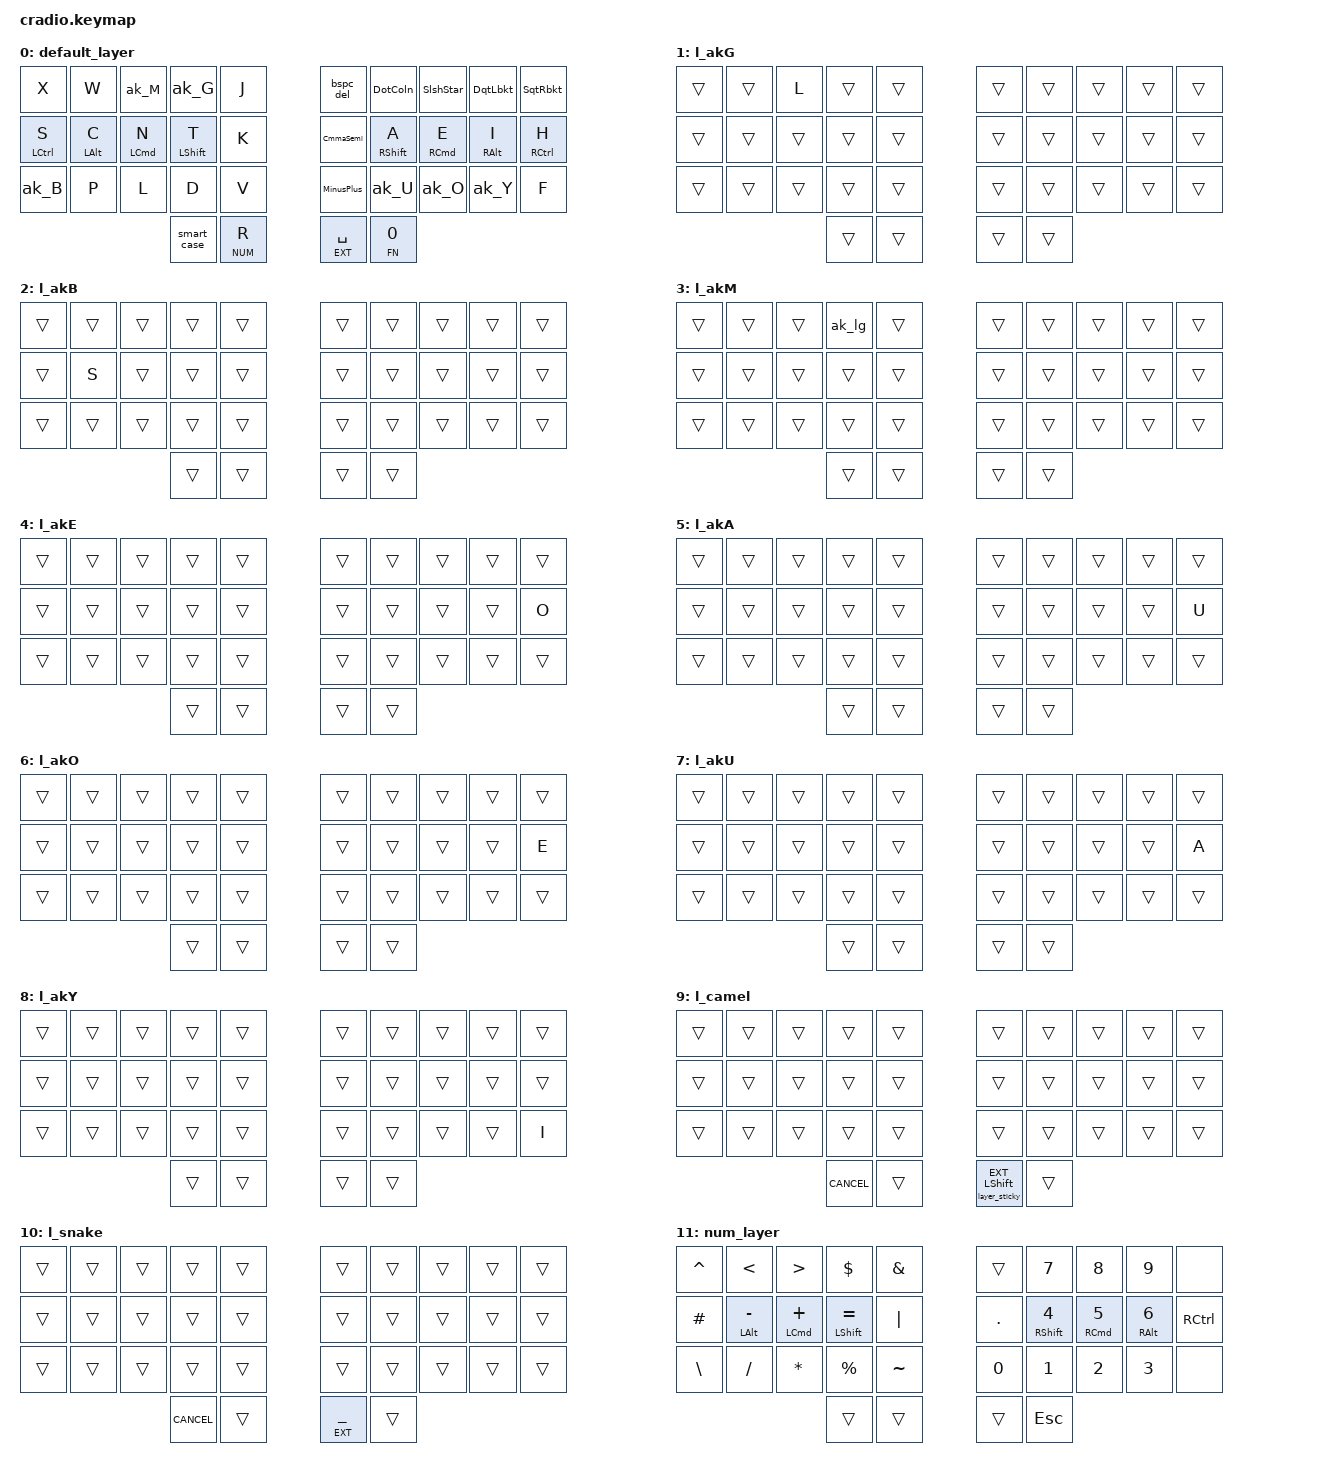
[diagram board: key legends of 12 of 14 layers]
#include <behaviors.dtsi>
#include <dt-bindings/zmk/keys.h>
#include <dt-bindings/zmk/bt.h>

#include "../zmk-nodefree-config/helper.h"
#include "../zmk-nodefree-config/keypos_def/keypos_34keys.h"

#define KEYS_L LT0 LT1 LT2 LT3 LT4 LM0 LM1 LM2 LM3 LM4 LB0 LB1 LB2 LB3 LB4
#define KEYS_R RT0 RT1 RT2 RT3 RT4 RM0 RM1 RM2 RM3 RM4 RB0 RB1 RB2 RB3 RB4
#define KEYS_T LH1 LH0 RH0 RH1

#define XXX &none
#define ___ &trans

/* Global settings */

#define HM_TAPPING_TERM 280
#define HM_TAPPING_TERM_FAST 200
#define LAYER_TAPPING_TERM 200
#define AK_TAPPING_TERM 40
#define LK_TAPPING_TERM 200
#define QUICK_TAP_MS 175

&sk {  // sticky-key config
    release-after-ms = <600>;  // release after 0.6s
    quick-release;             // no double capitalization when rolling keys
};

&sl {  // sticky-layer config
    ignore-modifiers;          // allow chording sticky mods & layers
};

&lt {  // layer-tap config
    flavor = "balanced";
    tapping-term-ms = <LAYER_TAPPING_TERM>;
    quick-tap-ms = <QUICK_TAP_MS>;
};

#define ZMK_MACRO_FAST(NAME, ...) \
    ZMK_BEHAVIOR(NAME, macro, \
        wait-ms = <0>; \
        tap-ms = <0>; \
        bindings = __VA_ARGS__ ; \
    )

ZMK_BEHAVIOR(long_sticky, sticky_key,
    bindings = <&kp>;
    release-after-ms = <5000>;
    quick-release;)

ZMK_BEHAVIOR(layer_sticky, hold_tap,
    flavor = "balanced";
    tapping-term-ms = <LAYER_TAPPING_TERM>;
    quick-tap-ms = <QUICK_TAP_MS>;
    bindings = <&mo>, <&long_sticky>;)

/* Layers */

#define ALPHA 0
#define l_akG 1
#define l_akB 2
#define l_akM 3
#define l_akE 4
#define l_akA 5
#define l_akO 6
#define l_akU 7
#define l_akY 8
#define l_camel 9
#define l_snake 10
#define NUM 11
#define EXT 12
#define FN 13
#define ALPHA_ALL ALPHA l_akG l_akB l_akM l_akE l_akA l_akO l_akU l_akY l_camel l_snake

/* Homerow mods */

#define MAKE_HRM(NAME, HOLD, TAP, TRIGGER_POS) \
    ZMK_BEHAVIOR(NAME, hold_tap, \
        flavor = "balanced"; \
        tapping-term-ms = <HM_TAPPING_TERM>; \
        quick-tap-ms = <QUICK_TAP_MS>; \
        require-prior-idle-ms = <170>; \
        bindings = <HOLD>, <TAP>; \
        hold-trigger-key-positions = <TRIGGER_POS>; \
        hold-trigger-on-release; \
    )

MAKE_HRM(hml, &kp, &kp, KEYS_R KEYS_T)
MAKE_HRM(hmr, &kp, &kp, KEYS_L KEYS_T)

MAKE_HRM(hrm_a, &kp, &ak_A, KEYS_L KEYS_T)
MAKE_HRM(hrm_e, &kp, &ak_E, KEYS_L KEYS_T)

// Smart case

ZMK_BEHAVIOR(lt_oss, hold_tap,
    flavor = "balanced";
    tapping-term-ms = <LAYER_TAPPING_TERM>;
    quick-tap-ms = <QUICK_TAP_MS>;
    bindings = <&mo>, <&smart_case>;
)

// tap: sticky-shift | shift + tap/ double-tap: caps-word | hold: shift
// cmd + tap: camelCase | shift + cmd + tap: PascalCase
// alt + tap: snake_case | shift + alt + tap: SCREAM_SNAKE_CASE
ZMK_BEHAVIOR(smart_case, mod_morph,
    bindings = <&smart_case2>, <&camel_pascal>;
    mods = <(MOD_RGUI)>;
)
ZMK_BEHAVIOR(smart_case2, mod_morph,
    bindings = <&smart_case3>, <&scream_smart_case>;
    mods = <(MOD_RSFT|MOD_LSFT)>;
)
ZMK_MACRO_FAST(scream_smart_case, <&scream_case &smart_case3>)
ZMK_BEHAVIOR(smart_case3, mod_morph,
    bindings = <&smart_shft>, <&snake_case>;
    mods = <(MOD_RALT)>;
)

ZMK_BEHAVIOR(smart_shft, mod_morph,
    bindings = <&sk LSHFT>, <&caps_word>;
    mods = <(MOD_LSFT)>;
)
&caps_word {  // mods deactivate caps-word, requires PR #1441
    /delete-property/ ignore-modifiers;
};

ZMK_BEHAVIOR(camel_pascal, mod_morph,
    bindings = <&camel_case>, <&pascal_case>;
    mods = <(MOD_RSFT)>;
)
ZMK_BEHAVIOR(camel_case, caps_word,
    layers = <l_camel>;
    ignore-alphas;
    ignore-numbers;
    continue-list = <BSPC DEL UNDER MINUS FSLH>;
)
ZMK_BEHAVIOR(snake_case, caps_word,
    layers = <l_snake>;
    ignore-alphas;
    ignore-numbers;
    continue-list = <BSPC DEL UNDER MINUS FSLH>;
)
ZMK_BEHAVIOR(scream_case, caps_word,
    mods = <MOD_LSFT>;
    ignore-alphas;
    ignore-numbers;
    continue-list = <BSPC DEL UNDER MINUS FSLH>;
)
ZMK_MACRO_FAST(pascal_case,
    <&camel_case &long_sticky LSHFT>
)

// Num word

// tap: num-word | double-tap: sticky num-layer | hold: num-layer
#define SMART_NUM &smart_num NUM 0
ZMK_BEHAVIOR(smart_num, hold_tap,
    flavor = "balanced";
    tapping-term-ms = <LAYER_TAPPING_TERM>;
    quick-tap-ms = <QUICK_TAP_MS>;
    bindings = <&mo>, <&num_dance>;
)
ZMK_BEHAVIOR(num_dance, tap_dance,
    tapping-term-ms = <LAYER_TAPPING_TERM>;
    bindings = <&num_word>, <&sl NUM>;  // reverse this for sticky-num on single tap
)
&num_word {  // num-word, requires PR #1441
    layers = <NUM>;
    continue-list = <BSPC DEL DOT COMMA PLUS MINUS STAR FSLH EQUAL>;
};

// Alt+Tab swapper
ZMK_BEHAVIOR(swapper, tri_state,
    bindings = <&kt LCMD>, <&kp TAB>, <&kt LCMD>;
    ignored-key-positions = <LT2>;
)

/* Combos */

#undef COMBO_TERM
#define COMBO_TERM 40
#define COMBO_TERM_FAST 30
#define COMBO_TERM_SLOW 40
#define COMBO_TERM_VERT 70

// h-digraph combos

ZMK_COMBO(combo_wh,   &Wh,                      LT3 LT2,     ALPHA_ALL, COMBO_TERM_FAST)
ZMK_COMBO(combo_gh,   &Gh,                      LT2 LT1,     ALPHA_ALL, COMBO_TERM_FAST)
ZMK_COMBO(combo_ght,  &ght,                     LT3 LT2 LT1, ALPHA_ALL, COMBO_TERM_SLOW)
MAKE_HRM(hm_sh, &kp,  &Sh, KEYS_L KEYS_T)
ZMK_COMBO(combo_sh,   &hm_sh LC(LALT) 0,        LM4 LM3,     ALPHA_ALL, COMBO_TERM_FAST)
MAKE_HRM(hm_sch, &kp, &Sch, KEYS_L KEYS_T)
ZMK_COMBO(combo_sch,  &hm_sch LC(LA(LCMD)) 0,   LM4 LM3 LM2, ALPHA_ALL, COMBO_TERM_SLOW)
MAKE_HRM(hm_ch, &kp,  &Ch, KEYS_L KEYS_T)
ZMK_COMBO(combo_ch,   &hm_ch LA(LCMD) 0,        LM3 LM2,     ALPHA_ALL, COMBO_TERM_FAST)
MAKE_HRM(hm_th, &kp,  &Th, KEYS_L KEYS_T)
ZMK_COMBO(combo_th,   &hm_th LG(LSHFT) 0,       LM2 LM1,     ALPHA_ALL, COMBO_TERM_FAST)
MAKE_HRM(hm_tch, &kp, &Tch, KEYS_L KEYS_T)
ZMK_COMBO(combo_tch,  &hm_tch LA(LG(LSHFT)) 0,  LM3 LM2 LM1, ALPHA_ALL, COMBO_TERM_SLOW)
ZMK_COMBO(combo_ph,   &Ph,                      LB3 LB2,     ALPHA_ALL, COMBO_TERM_FAST)

// editing combos

ZMK_COMBO(undo, &kp LG(Z),       LB4 LB3,     ALL, COMBO_TERM_FAST)
ZMK_COMBO(redo, &kp LG(LS(Z)),   LB4 LB3 LB2, ALL, COMBO_TERM_SLOW)
ZMK_COMBO(cut,  &kp LG(X),       LB3 LB2 LB1, ALL, COMBO_TERM_SLOW)
ZMK_COMBO(copy, &kp LG(C),       LB3 LB1,     ALL, COMBO_TERM_SLOW)
ZMK_COMBO(pste, &kp LG(V),       LB2 LB1,     ALL, COMBO_TERM_FAST)

ZMK_COMBO(combo_esc, &hmr RG(RSHFT) ESC, RM1 RM2, ALL, COMBO_TERM_FAST)
ZMK_COMBO(combo_esc_vert, &kp ESC,       RT1 RM1, ALL, COMBO_TERM_VERT)
ZMK_COMBO(combo_ret, &hmr RG(RSHFT) RET, RB1 RB2, ALL, COMBO_TERM_FAST)

// glyph combos

ZMK_COMBO(combo_qu,      &lk_qu,  LT3 LT1, ALPHA_ALL, 80)
ZMK_COMBO(combo_z,       &kp Z,   LT4 LT3, ALPHA_ALL, COMBO_TERM_SLOW)
ZMK_COMBO(combo_qu_vert, &lk_qu,  LT3 LM3, ALPHA_ALL, COMBO_TERM_VERT)
ZMK_COMBO(combo_z_vert,  &kp Z,   LT4 LM4, ALPHA_ALL, COMBO_TERM_VERT)

ZMK_COMBO(combo_colon, &kp COLON,         RT1 RT3, ALPHA_ALL, COMBO_TERM_SLOW)
ZMK_COMBO(combo_excl,  &kp EXCL,          RT1 RT2, ALPHA_ALL, COMBO_TERM_FAST)
ZMK_COMBO(combo_qmark, &kp QMARK,         RT2 RT3, ALPHA_ALL, COMBO_TERM_FAST)
ZMK_COMBO(combo_grave, &kp GRAVE,         RT3 RT4, ALPHA_ALL, COMBO_TERM_SLOW)
ZMK_COMBO(combo_at,    &kp AT,            RT0 RT1, ALPHA_ALL, COMBO_TERM_FAST)
ZMK_COMBO(combo_semi,  &kp SEMI,          RM0 RM1, ALPHA_ALL, COMBO_TERM_FAST)
ZMK_COMBO(combo_under, &kp UNDER,         RB1 RB3, ALPHA_ALL, COMBO_TERM_SLOW)
ZMK_COMBO(combo_equal, &kp EQUAL,         RB2 RB3, ALPHA_ALL, COMBO_TERM_FAST)
ZMK_COMBO(combo_ndash, &kp LA(MINUS),     RB0 RB1, ALPHA_ALL, COMBO_TERM_FAST) // N-dash
ZMK_COMBO(combo_mdash, &kp LA(LS(MINUS)), RB0 RB2, ALPHA_ALL, COMBO_TERM_SLOW) // M-dash

// macros for h-digraphs
    
ZMK_MACRO_FAST(Wh,
    <&macro_tap &kp W>
    , <&macro_release &kp LSHFT &kp RSHFT>
    , <&macro_tap &kp H>
)
ZMK_MACRO_FAST(Gh,
    <&macro_tap &kp G>
    , <&macro_release &kp LSHFT &kp RSHFT>
    , <&macro_tap &kp H>
)
ZMK_MACRO_FAST(ght, <&kp G &kp H &kp T>)
ZMK_MACRO_FAST(Sh,
    <&macro_tap &kp S>
    , <&macro_release &kp LSHFT &kp RSHFT>
    , <&macro_tap &kp H>
)
ZMK_MACRO_FAST(Sch,
    <&macro_tap &kp S>
    , <&macro_release &kp LSHFT &kp RSHFT>
    , <&macro_tap &kp C &kp H>
)
ZMK_MACRO_FAST(Ch,
    <&macro_tap &kp C>
    , <&macro_release &kp LSHFT &kp RSHFT>
    , <&macro_tap &kp H>
)
ZMK_MACRO_FAST(Th,
    <&macro_tap &kp T>
    , <&macro_release &kp LSHFT &kp RSHFT>
    , <&macro_tap &kp H>
)
ZMK_MACRO_FAST(Tch,
    <&macro_tap &kp T>
    , <&macro_release &kp LSHFT &kp RSHFT>
    , <&macro_tap &kp C &kp H>
)
ZMK_MACRO_FAST(Ph,
    <&macro_tap &kp P>
    , <&macro_release &kp LSHFT &kp RSHFT>
    , <&macro_tap &kp H>
)

/* Mod morphs */

ZMK_BEHAVIOR(CmmaSemi, mod_morph,
    mods = <(MOD_LSFT|MOD_RSFT)>;
    bindings = <&kp COMMA>, <&typeSemi>;
)
ZMK_BEHAVIOR(typeSemi, macro,
    bindings = <&macro_release &kp LSHFT>
            , <&macro_tap &kp SEMICOLON>;
)
ZMK_BEHAVIOR(DotColn, mod_morph,
    mods = <(MOD_LSFT|MOD_RSFT)>;
    bindings = <&kp DOT>, <&kp COLON>;
)
ZMK_BEHAVIOR(SlshStar, mod_morph,
    mods = <(MOD_LSFT|MOD_RSFT)>;
    bindings = <&kp FSLH>, <&kp STAR>;
)
ZMK_BEHAVIOR(MinusPlus, mod_morph,
    mods = <(MOD_LSFT|MOD_RSFT)>;
    bindings = <&kp MINUS>, <&kp PLUS>;
)
ZMK_BEHAVIOR(DqtLbkt, mod_morph,
    mods = <(MOD_LSFT|MOD_RSFT)>;
    bindings = <&kp DQT>, <&kp LBKT>;
)
ZMK_BEHAVIOR(SqtRbkt, mod_morph,
    mods = <(MOD_LSFT|MOD_RSFT)>;
    bindings = <&kp SQT>, <&kp RBKT>;
)

ZMK_BEHAVIOR(qexl, mod_morph,
    mods = <(MOD_LSFT|MOD_RSFT)>;
    bindings = <&kp QMARK>, <&kp EXCL>;
)

ZMK_BEHAVIOR(dunder, mod_morph,
    mods = <(MOD_LSFT|MOD_RSFT)>;
    bindings = <&kp MINUS>, <&kp UNDER>;
)

ZMK_BEHAVIOR(bspc_del, mod_morph,
    mods = <(MOD_LSFT|MOD_RSFT)>;
    bindings = <&kp BSPC>, <&kp DEL>;
)

ZMK_BEHAVIOR(esc_cancel, macro,
    bindings = <&kp ESC &kp K_CANCEL>;
)

/* Adaptive Keys */

ZMK_BEHAVIOR(ak, sticky_key,
    bindings = <&mo>;
    release-after-ms = <AK_TAPPING_TERM>;
    quick-release;
)

#define MACRO_CHOOSER2(_1, _2, FUNC, ...) FUNC
#define AK(...) MACRO_CHOOSER2(__VA_ARGS__, AK2, AK1)(__VA_ARGS__)
#define AK2(KEY, LAYER) ZMK_MACRO_FAST(ak_##KEY, \
    <&macro_tap &kp KEY>, \
    <&macro_press &mo l_ak##LAYER>, \
    <&macro_pause_for_release>, \
    <&macro_release &mo l_ak##LAYER>, \
    <&ak l_ak##LAYER>)
#define AK1(KEY) AK2(KEY, KEY)

AK2(G, G)
AK2(B, B)
AK2(M, M)
AK2(A, A)
AK2(U, U)
AK2(E, E)
AK2(O, O)
AK2(Y, Y)

ZMK_MACRO_FAST(ak_lg, <&kp BSPC &kp L &kp G>)

/* Linger Keys */

#define LK(NAME, HOLD, TAP) ZMK_BEHAVIOR(NAME, hold_tap, \
    flavor = "tap-preferred"; \
    tapping-term-ms = <LK_TAPPING_TERM>; \
    bindings = <HOLD>, <TAP>; \
)

ZMK_MACRO_FAST(lk_qu,
    <&macro_tap &kp Q>,
    <&macro_press &lk_qu_u U 0>,
    <&macro_pause_for_release>,
    <&macro_release &lk_qu_u U 0>)
// LK(lk_qu, &kp, &Qu)
// only add the 'u' when rolling onto another key
// FIXME: not working
ZMK_BEHAVIOR(lk_qu_u, hold_tap,
    flavor = "tap-unless-interrupted";
    tapping-term-ms = <500>;
    bindings = <&kp>, <&none>;
)

// keymap

ZMK_LAYER(default_layer,
&kp X         &kp W        &ak_M        &ak_G          &kp J        &bspc_del      &DotColn        &SlshStar      &DqtLbkt     &SqtRbkt
&hml LCTRL S  &hml LALT C  &hml LCMD N  &hml LSHFT T   &kp K        &CmmaSemi      &hrm_a RSHFT A  &hrm_e RCMD E  &hmr RALT I  &hmr RCTRL H
&ak_B         &kp P        &kp L        &kp D          &kp V        &MinusPlus     &ak_U           &ak_O          &ak_Y        &kp F
                                        &smart_case    &lt NUM R    &lt EXT SPACE  &lt_oss FN 0 
)

ZMK_LAYER(l_akG,
___     ___     &kp L   ___     ___    ___     ___     ___     ___     ___
___     ___     ___     ___     ___    ___     ___     ___     ___     ___
___     ___     ___     ___     ___    ___     ___     ___     ___     ___
                        ___     ___    ___     ___
)

ZMK_LAYER(l_akB,
___     ___     ___     ___     ___    ___     ___     ___     ___     ___
___     &kp S   ___     ___     ___    ___     ___     ___     ___     ___
___     ___     ___     ___     ___    ___     ___     ___     ___     ___
                        ___     ___    ___     ___
)

ZMK_LAYER(l_akM,
___     ___     ___     &ak_lg  ___    ___     ___     ___     ___     ___
___     ___     ___     ___     ___    ___     ___     ___     ___     ___
___     ___     ___     ___     ___    ___     ___     ___     ___     ___
                        ___     ___    ___     ___
)

ZMK_LAYER(l_akE,
___     ___     ___     ___     ___    ___     ___     ___     ___     ___
___     ___     ___     ___     ___    ___     ___     ___     ___     &kp O
___     ___     ___     ___     ___    ___     ___     ___     ___     ___
                        ___     ___    ___     ___
)

// a after e to resolve timing issues when typing "eau" fast
ZMK_LAYER(l_akA,
___     ___     ___     ___     ___    ___     ___     ___     ___     ___
___     ___     ___     ___     ___    ___     ___     ___     ___     &kp U
___     ___     ___     ___     ___    ___     ___     ___     ___     ___
                        ___     ___    ___     ___
)

ZMK_LAYER(l_akO,
___     ___     ___     ___     ___    ___     ___     ___     ___     ___
___     ___     ___     ___     ___    ___     ___     ___     ___     &kp E
___     ___     ___     ___     ___    ___     ___     ___     ___     ___
                        ___     ___    ___     ___
)

ZMK_LAYER(l_akU,
___     ___     ___     ___     ___    ___     ___     ___     ___     ___
___     ___     ___     ___     ___    ___     ___     ___     ___     &kp A
___     ___     ___     ___     ___    ___     ___     ___     ___     ___
                        ___     ___    ___     ___
)

ZMK_LAYER(l_akY,
___     ___     ___     ___     ___    ___     ___     ___     ___     ___
___     ___     ___     ___     ___    ___     ___     ___     ___     ___
___     ___     ___     ___     ___    ___     ___     ___     ___     &kp I
                        ___     ___    ___     ___
)

ZMK_LAYER(l_camel,
___     ___     ___     ___     ___    ___     ___     ___     ___     ___
___     ___     ___     ___     ___    ___     ___     ___     ___     ___
___     ___     ___     ___     ___    ___     ___     ___     ___     ___
                   &kp K_CANCEL ___  &layer_sticky EXT LSHFT  ___
)

ZMK_LAYER(l_snake,
___     ___     ___     ___     ___    ___     ___     ___     ___     ___
___     ___     ___     ___     ___    ___     ___     ___     ___     ___
___     ___     ___     ___     ___    ___     ___     ___     ___     ___
                   &kp K_CANCEL ___  &lt EXT UNDER ___
)

ZMK_LAYER(num_layer,
&kp CARET  &kp LT           &kp GT          &kp DOLLAR        &kp AMPS     ___       &kp N7            &kp N8          &kp N9           XXX
&kp HASH   &hml LALT MINUS  &hml LCMD PLUS  &hml LSHFT EQUAL  &kp PIPE     &kp DOT   &hmr RSHFT N4     &hmr RCMD N5    &hmr RALT N6     &kp RCTRL
&kp BSLH   &kp FSLH         &kp STAR        &kp PRCNT         &kp TILDE    &kp N0    &kp N1            &kp N2          &kp N3           XXX
                                            ___               ___          ___       &kp ESC   
)


ZMK_LAYER(ext_layer,
&kp Z      &kp Q           &kp LBRC        &kp RBRC          XXX          &kp PG_UP  &kp HOME         &kp UP          &kp END          XXX 
&kp LCTRL  &kp LALT        &hml LCMD LPAR  &hml LSHFT RPAR   XXX          &kp PG_DN  &hmr RSHFT LEFT  &hmr RCMD DOWN  &hmr RALT RIGHT  &kp RCTRL
XXX        XXX             &kp LBKT        &kp RBKT          XXX          &none      &kp BSPC         &kp TAB         &kp DEL          XXX 
                                           &kp LS(TAB)       &swapper     ___        ___   
)

ZMK_LAYER(fn_layer,
XXX        &kp C_PREV  &kp C_PP      &kp C_NEXT    &bootloader    &bootloader  &kp F7  &kp F8  &kp F9  &kp F12
&kp LCTRL  &kp LALT    &kp LCMD      &kp LSHFT     &sys_reset     &sys_reset   &kp F4  &kp F5  &kp F6  &kp F11
XXX        &kp C_MUTE  &kp C_VOL_DN  &kp C_VOL_UP  XXX            XXX          &kp F1  &kp F2  &kp F3  &kp F10
                                     &kp K_CANCEL  ___            ___          ___   
)
